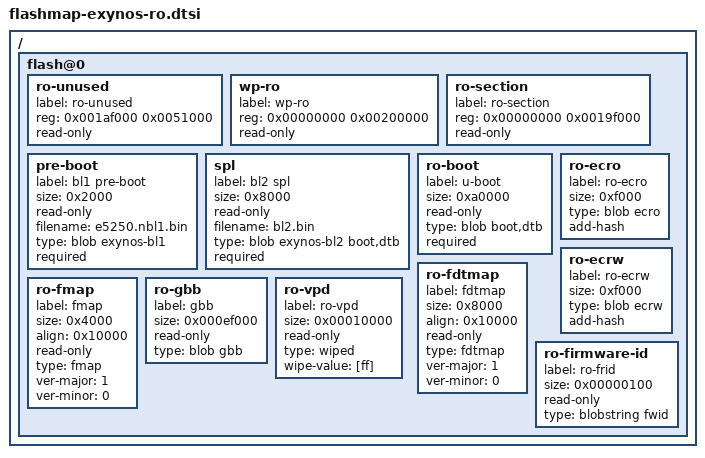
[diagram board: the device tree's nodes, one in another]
/*
 * Copyright (c) 2012 The Chromium OS Authors. All rights reserved.
 * Use of this source code is governed by a BSD-style license that can be
 * found in the LICENSE file.
 */

/*
 * This is a sub-fmap embedded into the main fmap. This sub-fmap defines
 * the layout of the read-only portion.
 */

/ {
	/*
	 * Labels have been selected to be to compatible with existing tools,
	 * even thought the terminology may be a little different on ARM.
	 * Names will be capitalized and hyphen converted to underscore by
	 * cros_bundle_firmware.
	 *
	 * This map is optimized to fit into 1MB. We may or may not get away
	 * with something this small. 512KB would be even better but that
	 * seems a bit too brave at present.
	 */
	flash@0 {
		/* ---- Section: Read-only ---- */
		ro-unused {
			label = "ro-unused";
			reg = <0x001af000 0x0051000>;
			read-only;
		};

		wp-ro {
			label = "wp-ro";
			reg = <0x00000000 0x00200000>;
			read-only;
		};

		ro-section {
			label = "ro-section";
			reg = <0x00000000 0x0019f000>;
			read-only;
		};

		pre-boot {
			label = "bl1 pre-boot";
			size = <0x2000>;
			read-only;
			filename = "e5250.nbl1.bin";
			type = "blob exynos-bl1";
			required;
		};

		spl {
			label = "bl2 spl";
			size = <0x8000>;
			read-only;
			filename = "bl2.bin";
			type = "blob exynos-bl2 boot,dtb";
			required;
		};

		ro-boot {
			label = "u-boot";
			size = <0xa0000>;
			read-only;
			type = "blob boot,dtb";
			required;
		};

		ro-ecro {
			label = "ro-ecro";
			size = <0xf000>;
			type = "blob ecro";
			add-hash;
		};

		ro-ecrw {
			label = "ro-ecrw";
			size = <0xf000>;
			type = "blob ecrw";
			add-hash;
		};

		ro-fdtmap {
			label = "fdtmap";

			/* We encourage to align FDTMAP partition in as large
			 * block as possible so that flashrom can find it soon.
			 * For example, aligning to 512KB is better than to
			 * 256KB. */
			size = <0x8000>;
			align = <0x10000>;
			read-only;
			type = "fdtmap";
			ver-major = <1>;
			ver-minor = <0>;
		};

		/*
		 * Add an FMAP for backwards compatibility for now. This is
		 * needed by dump_fmap which is used by the firmware signer.
		 */
		ro-fmap {
			label = "fmap";
			size = <0x4000>;
			align = <0x10000>;
			read-only;
			type = "fmap";
			ver-major = <1>;
			ver-minor = <0>;
		};

		ro-gbb {
			label = "gbb";

			/* GBB offset must be aligned to 4K bytes */
			size = <0x000ef000>;
			read-only;
			type = "blob gbb";
		};

		/* ---- Section: Vital-product data (VPD) ---- */
		ro-vpd {
			label = "ro-vpd";

			/* VPD offset must be aligned to 4K bytes */
			size = <0x00010000>;
			read-only;
			type = "wiped";
			wipe-value = [ff];
		};

		ro-firmware-id {
			label = "ro-frid";
			size = <0x00000100>;
			read-only;
			type = "blobstring fwid";
		};
	};
};
